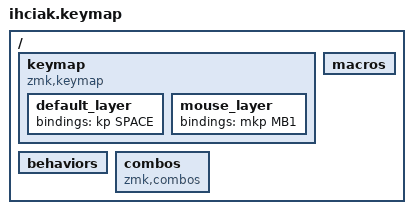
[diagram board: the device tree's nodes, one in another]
/*
 * Copyright (c) 2025 The ZMK Contributors
 * SPDX-License-Identifier: MIT
 */

#include <behaviors.dtsi>
#include <dt-bindings/zmk/keys.h>
#include <dt-bindings/zmk/bt.h>
#include <dt-bindings/zmk/outputs.h>
#include <dt-bindings/zmk/mouse.h>

/ {
    keymap {
        compatible = "zmk,keymap";

        default_layer {
            bindings = <
                &kp SPACE
            >;
        };

        mouse_layer {
            bindings = <
                &mkp MB1  // マウスの左クリックとして機能
            >;
        };
    };

    behaviors {
        // カスタムビヘイビアの定義があれば追加
    };

    combos {
        compatible = "zmk,combos";
        // コンボの定義があれば追加
    };

    macros {
        // マクロの定義があれば追加
    };
};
